# MDR32F9Q2I register map
Vendor: Milandr; File version: 1.0
CPU: CM3 r1p1, little endian, MPU, no FPU, 3 interrupt priority bits
Registers are 32-bit, read-write, reset 0x0 unless marked. A register's access mark holds for its fields unless they carry their own. Offsets are from the block's base; [hi:lo] are bit positions; {n}, {i} and the like mark numbered series; 'fields as' and 'values as' point back to an identical list.

## MDR_USB — USB interface controller registers
Base 0x40010000
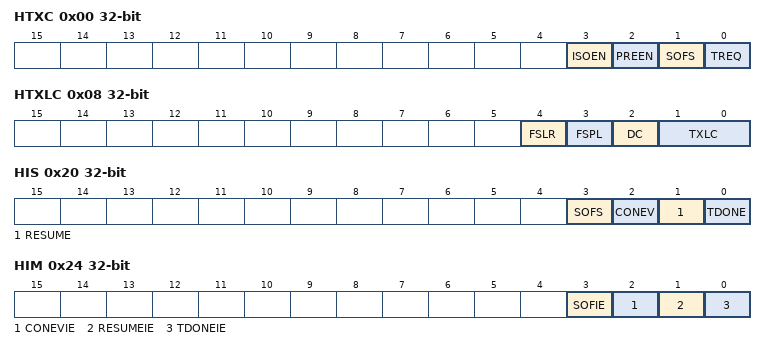
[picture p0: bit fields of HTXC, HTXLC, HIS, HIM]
0x00 HTXC — USB HTXC Register
  [3] ISOEN, [2] PREEN, [1] SOFS, [0] TREQ
0x04 HTXT — USB HTXT Register
  [1:0] TTYPE
0x08 HTXLC — USB HTXLC Register
  [4] FSLR, [3] FSPL, [2] DC, [1:0] TXLC
0x0C HTXSE
  [0] SOFEN
0x10 HTXA
  [6:0] DEVADDR
0x14 HTXE
  [3:0] EPADDR
0x18 HFN_L
  [7:0] FNUM
0x1C HFN_H
  [2:0] FNUM
0x20 HIS — USB_HIS Register
  [3] SOFS, [2] CONEV, [1] RESUME, [0] TDONE
0x24 HIM — USB_HIM Register
  [3] SOFIE, [2] CONEVIE, [1] RESUMEIE, [0] TDONEIE
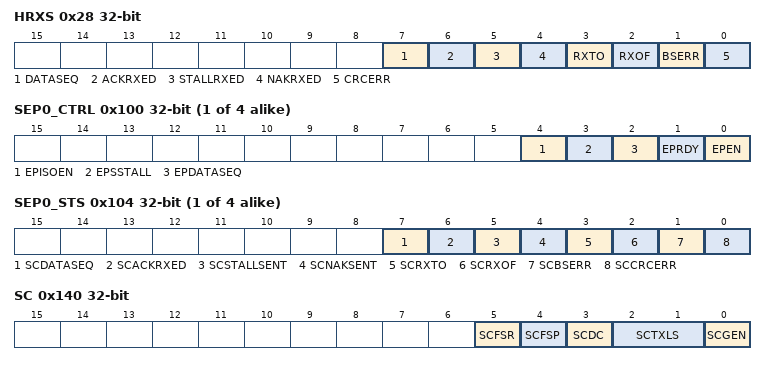
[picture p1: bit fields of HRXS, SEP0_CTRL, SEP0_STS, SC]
0x28 HRXS — USB_HRXS Register
  [7] DATASEQ, [6] ACKRXED, [5] STALLRXED, [4] NAKRXED, [3] RXTO, [2] RXOF, [1] BSERR, [0] CRCERR
0x2C HRXP
  [3:0] RPID
0x30 HRXA
  [6:0] RADDR
0x34 HRXE
  [3:0] RENDP
0x38 HRXCS
  [1:0] RXLS
0x3C HSTM
  [7:0] HSTM
0x80 HRXFD
  [7:0] RXFIFODATA
0x88 HRXFDC_L
  [7:0] FIFODATACOUNT
0x8C HRXFDC_H
  [7:0] FIFODATACOUNT
0x90 HRXFC
  [0] FIFOFORCEEMPTY
0xC0 HTXFD
  [7:0] TXFIFODATA
0xD0 HTXFC
  [0] FIFOFORCEEMPTY
{0x100+0x10*i} SEP{i}_CTRL (i=0..3) — USB_SEP Control Register
  [4] EPISOEN, [3] EPSSTALL, [2] EPDATASEQ, [1] EPRDY, [0] EPEN
{0x104+0x10*i} SEP{i}_STS (i=0..3) — USB_SEP Status Register
  [7] SCDATASEQ, [6] SCACKRXED, [5] SCSTALLSENT, [4] SCNAKSENT, [3] SCRXTO, [2] SCRXOF, [1] SCBSERR, [0] SCCRCERR
{0x108+0x10*i} SEP{i}_TS (i=0..3)
  [1:0] SCTTYPE
{0x10C+0x10*i} SEP{i}_NTS (i=0..3)
  [1:0] NTTYPE
0x140 SC — USB_SC Register
  [5] SCFSR, [4] SCFSP, [3] SCDC, [2:1] SCTXLS, [0] SCGEN
0x144 SLS
  [1:0] SCRXLS
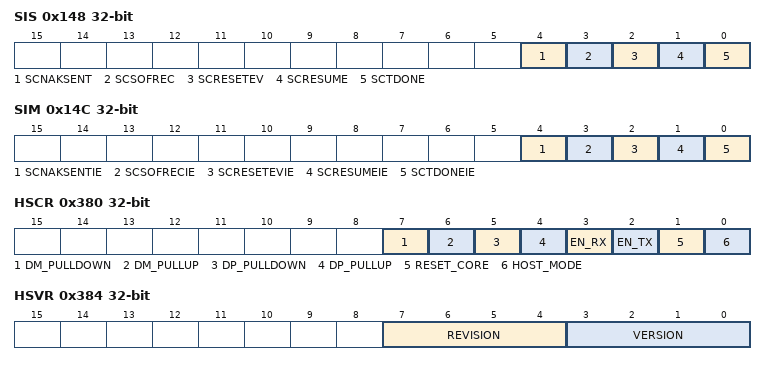
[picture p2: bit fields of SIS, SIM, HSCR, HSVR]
0x148 SIS — USB_SIS Register
  [4] SCNAKSENT, [3] SCSOFREC, [2] SCRESETEV, [1] SCRESUME, [0] SCTDONE
0x14C SIM — USB_SIM Register
  [4] SCNAKSENTIE, [3] SCSOFRECIE, [2] SCRESETEVIE, [1] SCRESUMEIE, [0] SCTDONEIE
0x150 SA
  [6:0] SCDEVADDR
0x154 SFN_L
  [7:0] FRAMENUM
0x158 SFN_H
  [2:0] FRAMENUM
{0x180+0x80*i} SEP_FIFO{i}_RXFD (i=0..3)
  [7:0] RXFIFODATA
{0x188+0x80*i} SEP_FIFO{i}_RXFDC_L (i=0..3)
  [7:0] FIFODATACOUNT
{0x18C+0x80*i} SEP_FIFO{i}_RXFDC_H (i=0..3)
  [7:0] FIFODATACOUNT
{0x190+0x80*i} SEP_FIFO{i}_RXFC (i=0..3)
  [0] FIFOFORCEEMPTY
{0x1C0+0x80*i} SEP_FIFO{i}_TXFD (i=0..3)
  [7:0] TXFIFODATA
{0x1D0+0x80*i} SEP_FIFO{i}_TXFDC (i=0..3)
  [0] FIFOFORCEEMPTY
0x380 HSCR — USB_HSCR Register
  [7] DM_PULLDOWN, [6] DM_PULLUP, [5] DP_PULLDOWN, [4] DP_PULLUP, [3] EN_RX, [2] EN_TX, [1] RESET_CORE, [0] HOST_MODE
0x384 HSVR — USB_HSVR Register
  [7:4] REVISION, [3:0] VERSION

## MDR_EEPROM — Flash programm memory interface controller registers
Base 0x40018000
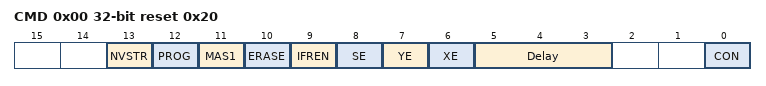
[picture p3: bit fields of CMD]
0x00 CMD reset 0x20 — EEPROM Command Register
  [13] NVSTR, [12] PROG, [11] MAS1, [10] ERASE, [9] IFREN, [8] SE, [7] YE, [6] XE, [5:3] Delay, [0] CON
0x04 ADR — EEPROM Address Register
0x08 DI — EEPROM Read Data Register
  [31:0] DATA
0x0C DO — EEPROM Write Data Register
  [31:0] DATA
0x10 KEY — EEPROM Key Register

## MDR_RST_CLK — RST_CLK
Base 0x40020000
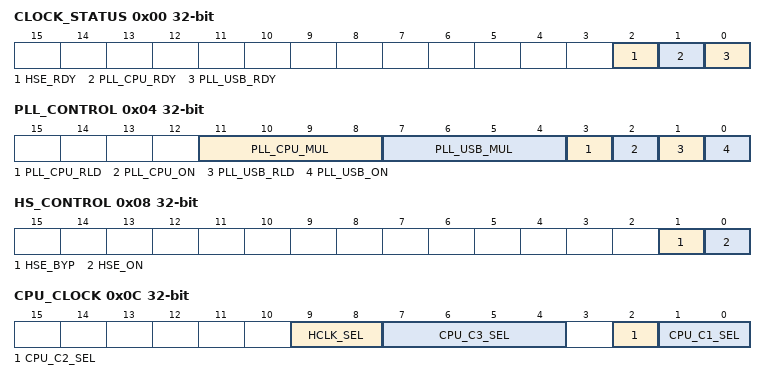
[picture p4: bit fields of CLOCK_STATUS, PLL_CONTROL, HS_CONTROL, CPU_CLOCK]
0x00 CLOCK_STATUS ro
  [2] HSE_RDY, [1] PLL_CPU_RDY, [0] PLL_USB_RDY
0x04 PLL_CONTROL
  [11:8] PLL_CPU_MUL, [7:4] PLL_USB_MUL, [3] PLL_CPU_RLD, [2] PLL_CPU_ON, [1] PLL_USB_RLD, [0] PLL_USB_ON
0x08 HS_CONTROL
  [1] HSE_BYP, [0] HSE_ON
0x0C CPU_CLOCK
  [9:8] HCLK_SEL
    0=HSI (HSI selected); 1=CPU_C3 (CPU_C3 selected); 2=LSE (LSE selected); 3=LSI (LSI selected)
  [7:4] CPU_C3_SEL
  [2] CPU_C2_SEL
    0=CPU_C1 (CPU_C1 selected); 1=PLLCPUo selected
  [1:0] CPU_C1_SEL
    0=HSI (HSI selected); 1=HSI/2 (HSI/2 selected); 2=HSE (HSE selected); 3=HSE/2 (HSE/2 selected)
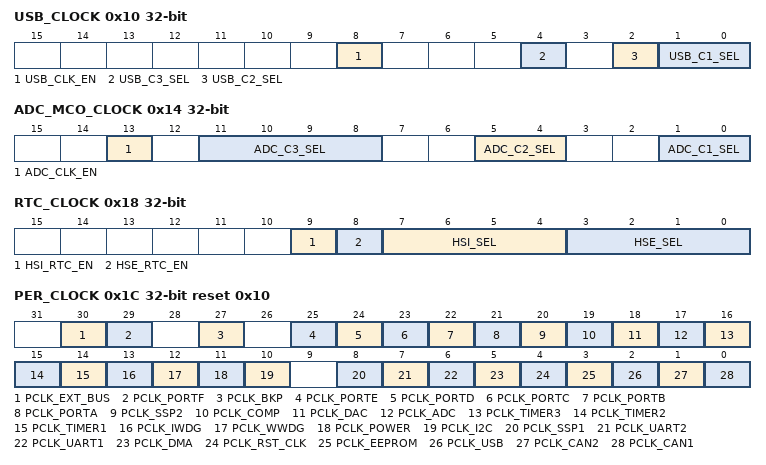
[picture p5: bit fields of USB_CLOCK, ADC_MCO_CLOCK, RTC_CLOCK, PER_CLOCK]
0x10 USB_CLOCK
  [8] USB_CLK_EN
  [4] USB_C3_SEL
    0=USB_C2 (USB_C2 selected); 1=USB_C2/2 (USB_C2/2 selected)
  [2] USB_C2_SEL
    0=USB_C1 (USB_C1 selected); 1=PLLUSBo selected
  [1:0] USB_C1_SEL
    values as CPU_CLOCK.CPU_C1_SEL
0x14 ADC_MCO_CLOCK — ADC Clock Register
  [13] ADC_CLK_EN
  [11:8] ADC_C3_SEL
  [5:4] ADC_C2_SEL
    0=LSE (LSE selected); 1=LSI (LSI selected); 2=ADC_C1 (ADC_C1 selected); 3=HSI_C1 (HSI_C1 selected)
  [1:0] ADC_C1_SEL
    0=CPU_C1 (CPU_C1 selected); 1=USB_C1 (USB_C1 selected); 2=CPU_C2 (CPU_C2 selected); 3=USB_C2 (USB_C2 selected)
0x18 RTC_CLOCK
  [9] HSI_RTC_EN, [8] HSE_RTC_EN, [7:4] HSI_SEL, [3:0] HSE_SEL
0x1C PER_CLOCK reset 0x10 — Peripheral Clock Enable Register
  [30] PCLK_EXT_BUS, [29] PCLK_PORTF, [27] PCLK_BKP, [25] PCLK_PORTE, [24] PCLK_PORTD, [23] PCLK_PORTC, [22] PCLK_PORTB, [21] PCLK_PORTA, [20] PCLK_SSP2, [19] PCLK_COMP, [18] PCLK_DAC, [17] PCLK_ADC, [16] PCLK_TIMER3, [15] PCLK_TIMER2, [14] PCLK_TIMER1, [13] PCLK_IWDG, [12] PCLK_WWDG, [11] PCLK_POWER, [10] PCLK_I2C, [8] PCLK_SSP1, [7] PCLK_UART2, [6] PCLK_UART1, [5] PCLK_DMA, [4] PCLK_RST_CLK, [3] PCLK_EEPROM, [2] PCLK_USB, [1] PCLK_CAN2, [0] PCLK_CAN1
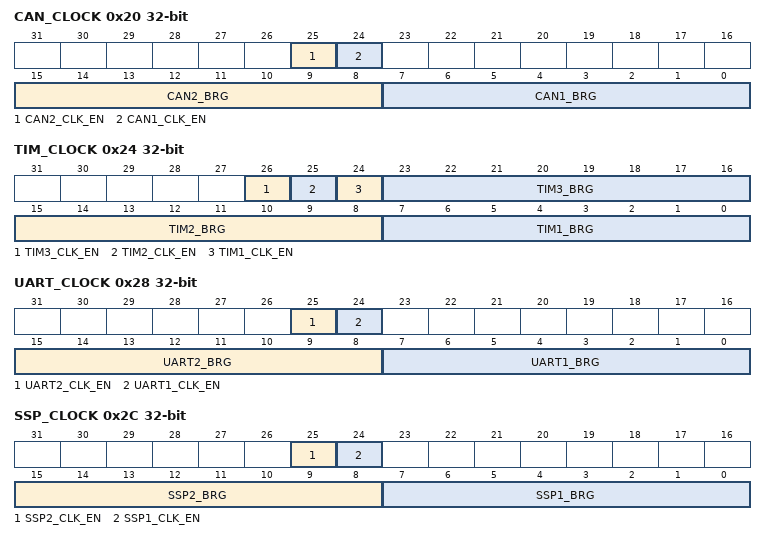
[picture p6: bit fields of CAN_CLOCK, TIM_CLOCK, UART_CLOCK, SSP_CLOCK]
0x20 CAN_CLOCK
  [25] CAN2_CLK_EN, [24] CAN1_CLK_EN, [15:8] CAN2_BRG, [7:0] CAN1_BRG
0x24 TIM_CLOCK — Timer Clock Register
  [26] TIM3_CLK_EN, [25] TIM2_CLK_EN, [24] TIM1_CLK_EN, [23:16] TIM3_BRG, [15:8] TIM2_BRG, [7:0] TIM1_BRG
0x28 UART_CLOCK
  [25] UART2_CLK_EN, [24] UART1_CLK_EN, [15:8] UART2_BRG, [7:0] UART1_BRG
0x2C SSP_CLOCK
  [25] SSP2_CLK_EN, [24] SSP1_CLK_EN, [15:8] SSP2_BRG, [7:0] SSP1_BRG
